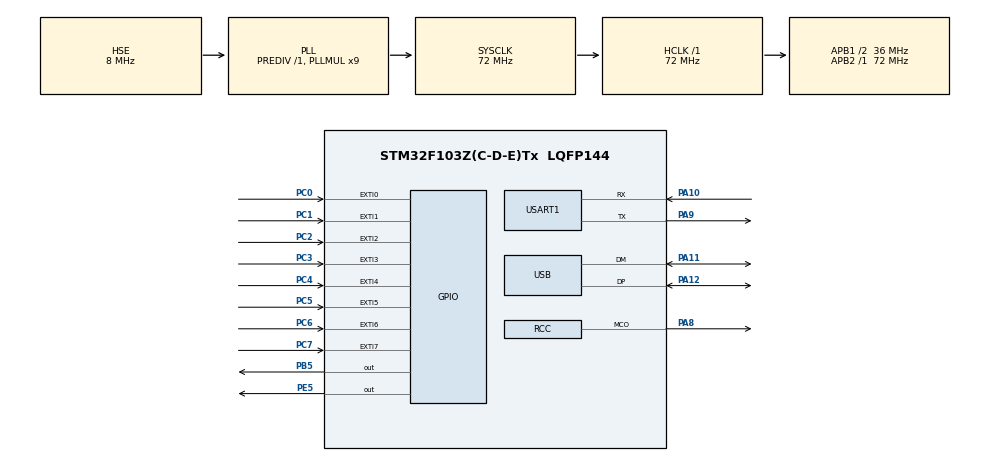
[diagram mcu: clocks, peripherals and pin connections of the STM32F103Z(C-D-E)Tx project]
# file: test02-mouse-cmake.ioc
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Dma.Request0=USART1_TX
Dma.Request1=USART1_RX
Dma.USART1_RX.1.Direction=DMA_PERIPH_TO_MEMORY
Dma.USART1_RX.1.Instance=DMA1_Channel5
Dma.USART1_RX.1.MemDataAlignment=DMA_MDATAALIGN_BYTE
Dma.USART1_RX.1.MemInc=DMA_MINC_ENABLE
Dma.USART1_RX.1.Mode=DMA_NORMAL
Dma.USART1_RX.1.PeriphDataAlignment=DMA_PDATAALIGN_BYTE
Dma.USART1_RX.1.PeriphInc=DMA_PINC_DISABLE
Dma.USART1_RX.1.Priority=DMA_PRIORITY_LOW
Dma.USART1_TX.0.Direction=DMA_MEMORY_TO_PERIPH
Dma.USART1_TX.0.Instance=DMA1_Channel4
Dma.USART1_TX.0.MemDataAlignment=DMA_MDATAALIGN_BYTE
Dma.USART1_TX.0.MemInc=DMA_MINC_ENABLE
Dma.USART1_TX.0.Mode=DMA_NORMAL
Dma.USART1_TX.0.PeriphDataAlignment=DMA_PDATAALIGN_BYTE
Dma.USART1_TX.0.PeriphInc=DMA_PINC_DISABLE
Dma.USART1_TX.0.Priority=DMA_PRIORITY_LOW
Mcu.Family=STM32F1
Mcu.Name=STM32F103Z(C-D-E)Tx
Mcu.Package=LQFP144
NVIC.DMA1_Channel4_IRQn=true\:0\:0\:false\:false\:true\:false\:true
NVIC.DMA1_Channel5_IRQn=true\:0\:0\:false\:false\:true\:false\:true
NVIC.EXTI0_IRQn=true\:0\:0\:false\:false\:true\:true\:true
NVIC.EXTI1_IRQn=true\:0\:0\:false\:false\:true\:true\:true
NVIC.EXTI2_IRQn=true\:0\:0\:false\:false\:true\:true\:true
NVIC.EXTI3_IRQn=true\:0\:0\:false\:false\:true\:true\:true
NVIC.EXTI4_IRQn=true\:0\:0\:false\:false\:true\:true\:true
NVIC.EXTI9_5_IRQn=true\:0\:0\:false\:false\:true\:true\:true
NVIC.PriorityGroup=NVIC_PRIORITYGROUP_4
NVIC.USART1_IRQn=true\:0\:0\:false\:false\:true\:true\:true
NVIC.USB_LP_CAN1_RX0_IRQn=true\:0\:0\:false\:false\:true\:false\:true
OSC_IN.Mode=HSE-External-Oscillator
OSC_IN.Signal=RCC_OSC_IN
OSC_OUT.Mode=HSE-External-Oscillator
OSC_OUT.Signal=RCC_OSC_OUT
PA10.Mode=Asynchronous
PA10.Signal=USART1_RX
PA11.Mode=Device
PA11.Signal=USB_DM
PA12.Mode=Device
PA12.Signal=USB_DP
PA13.Mode=Serial_Wire
PA13.Signal=SYS_JTMS-SWDIO
PA14.Mode=Serial_Wire
PA14.Signal=SYS_JTCK-SWCLK
PA8.Mode=Clock-out
PA8.Signal=RCC_MCO
PA9.Mode=Asynchronous
PA9.Signal=USART1_TX
PB5.GPIO_PuPd=GPIO_PULLDOWN
PB5.Signal=GPIO_Output
PC0.GPIO_PuPd=GPIO_PULLUP
PC0.Signal=GPXTI0
PC1.GPIO_PuPd=GPIO_PULLUP
PC1.Signal=GPXTI1
PC2.GPIO_PuPd=GPIO_PULLUP
PC2.Signal=GPXTI2
PC3.GPIO_ModeDefaultEXTI=GPIO_MODE_IT_RISING
PC3.GPIO_PuPd=GPIO_PULLUP
PC3.Signal=GPXTI3
PC4.GPIO_ModeDefaultEXTI=GPIO_MODE_IT_RISING_FALLING
PC4.GPIO_PuPd=GPIO_PULLUP
PC4.Signal=GPXTI4
PC5.GPIO_ModeDefaultEXTI=GPIO_MODE_IT_RISING_FALLING
PC5.GPIO_PuPd=GPIO_PULLUP
PC5.Signal=GPXTI5
PC6.GPIO_PuPd=GPIO_PULLUP
PC6.Signal=GPXTI6
PC7.GPIO_PuPd=GPIO_PULLUP
PC7.Signal=GPXTI7
PE5.GPIO_PuPd=GPIO_PULLDOWN
PE5.Signal=GPIO_Output
ProjectManager.HeapSize=0x400
ProjectManager.StackSize=0x400
ProjectManager.TargetToolchain=STM32CubeIDE
RCC.AHBFreq_Value=72000000
RCC.APB1CLKDivider=RCC_HCLK_DIV2
RCC.APB1Freq_Value=36000000
RCC.APB1TimFreq_Value=72000000
RCC.APB2Freq_Value=72000000
RCC.APB2TimFreq_Value=72000000
RCC.HCLKFreq_Value=72000000
RCC.PLLMUL=RCC_PLL_MUL9
RCC.PLLSourceVirtual=RCC_PLLSOURCE_HSE
RCC.RCC_MCOSource=RCC_MCO1SOURCE_PLLCLK
RCC.SYSCLKFreq_VALUE=72000000
RCC.SYSCLKSource=RCC_SYSCLKSOURCE_PLLCLK
RCC.USBFreq_Value=48000000
RCC.USBPrescaler=RCC_USBCLKSOURCE_PLL_DIV1_5
USART1.VirtualMode=VM_ASYNC
USB_DEVICE.CLASS_NAME_FS=HID
USB_DEVICE.VirtualMode=Hid
USB_DEVICE.VirtualModeFS=Hid_FS
VP_USB_DEVICE_VS_USB_DEVICE_HID_FS.Mode=HID_FS
board=custom

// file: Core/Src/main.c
/* USER CODE BEGIN Header */
/**
  ******************************************************************************
  * @file           : main.c
  * @brief          : Main program body
  ******************************************************************************
  * @attention
  *
  * <h2><center>&copy; Copyright (c) 2021 STMicroelectronics.
  * All rights reserved.</center></h2>
  *
  * This software component is licensed by ST under BSD 3-Clause license,
  * the "License"; You may not use this file except in compliance with the
  * License. You may obtain a copy of the License at:
  *                        opensource.org/licenses/BSD-3-Clause
  *
  ******************************************************************************
  */
/* USER CODE END Header */
#include "main.h"
#include "dma.h"
#include "usart.h"
#include "usb_device.h"
#include "gpio.h"

/* USER CODE BEGIN Includes */
#include "debug.h"
/* USER CODE END Includes */

void SystemClock_Config(void);

int main(void)
{

  /* MCU Configuration--------------------------------------------------------*/

  /* Reset of all peripherals, Initializes the Flash interface and the Systick. */
  HAL_Init();

  /* Configure the system clock */
  SystemClock_Config();

  /* Initialize all configured peripherals */
  MX_GPIO_Init();
  MX_DMA_Init();
  MX_USB_DEVICE_Init();
  MX_USART1_UART_Init();
  /* USER CODE BEGIN 2 */
    debug("start\n\r");
    uint8_t i = 0;
  /* USER CODE END 2 */

  /* Infinite loop */
  while (1)
  {

  }
}

void SystemClock_Config(void)
{
  RCC_OscInitTypeDef RCC_OscInitStruct = {0};
  RCC_ClkInitTypeDef RCC_ClkInitStruct = {0};
  RCC_PeriphCLKInitTypeDef PeriphClkInit = {0};

  /** Initializes the RCC Oscillators according to the specified parameters
  * in the RCC_OscInitTypeDef structure.
  */
  RCC_OscInitStruct.OscillatorType = RCC_OSCILLATORTYPE_HSE;
  RCC_OscInitStruct.HSEState = RCC_HSE_ON;
  RCC_OscInitStruct.HSEPredivValue = RCC_HSE_PREDIV_DIV1;
  RCC_OscInitStruct.HSIState = RCC_HSI_ON;
  RCC_OscInitStruct.PLL.PLLState = RCC_PLL_ON;
  RCC_OscInitStruct.PLL.PLLSource = RCC_PLLSOURCE_HSE;
  RCC_OscInitStruct.PLL.PLLMUL = RCC_PLL_MUL9;
  if (HAL_RCC_OscConfig(&RCC_OscInitStruct) != HAL_OK)
  {
    Error_Handler();
  }
  /** Initializes the CPU, AHB and APB buses clocks
  */
  RCC_ClkInitStruct.ClockType = RCC_CLOCKTYPE_HCLK|RCC_CLOCKTYPE_SYSCLK
                              |RCC_CLOCKTYPE_PCLK1|RCC_CLOCKTYPE_PCLK2;
  RCC_ClkInitStruct.SYSCLKSource = RCC_SYSCLKSOURCE_PLLCLK;
  RCC_ClkInitStruct.AHBCLKDivider = RCC_SYSCLK_DIV1;
  RCC_ClkInitStruct.APB1CLKDivider = RCC_HCLK_DIV2;
  RCC_ClkInitStruct.APB2CLKDivider = RCC_HCLK_DIV1;

  if (HAL_RCC_ClockConfig(&RCC_ClkInitStruct, FLASH_LATENCY_2) != HAL_OK)
  {
    Error_Handler();
  }
  PeriphClkInit.PeriphClockSelection = RCC_PERIPHCLK_USB;
  PeriphClkInit.UsbClockSelection = RCC_USBCLKSOURCE_PLL_DIV1_5;
  if (HAL_RCCEx_PeriphCLKConfig(&PeriphClkInit) != HAL_OK)
  {
    Error_Handler();
  }
  HAL_RCC_MCOConfig(RCC_MCO, RCC_MCO1SOURCE_PLLCLK, RCC_MCODIV_1);
}

void Error_Handler(void)
{
  __disable_irq();
  while (1)
  {
  }
}

/************************ (C) COPYRIGHT STMicroelectronics *****END OF FILE****/
